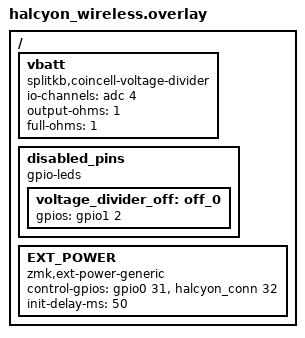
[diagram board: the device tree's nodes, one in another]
/ {
    vbatt: vbatt {
        compatible = "splitkb,coincell-voltage-divider";
        io-channels = <&adc 4>; // P0.28
        output-ohms = <1>;
        full-ohms = <1>;
    };

    disabled_pins {
        compatible = "gpio-leds";
        voltage_divider_off: off_0 {
            gpios = <&gpio1 2 GPIO_ACTIVE_HIGH>; // Configures GPIO 1.02 as Output + Inactive (0V). This ensures the lipo divider is OFF.
        };
    };

    EXT_POWER {
        compatible = "zmk,ext-power-generic";
        control-gpios = <&gpio0 31 GPIO_ACTIVE_HIGH>, <&halcyon_conn 32 GPIO_ACTIVE_HIGH>;
        init-delay-ms = <50>;
    };
};
